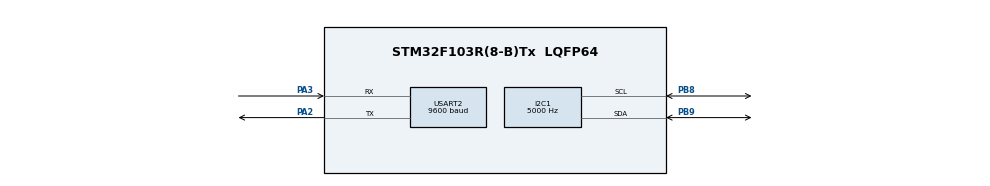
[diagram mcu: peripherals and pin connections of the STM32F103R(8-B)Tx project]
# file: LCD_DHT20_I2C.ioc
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I2C1.ClockSpeed=5000
Mcu.Family=STM32F1
Mcu.Name=STM32F103R(8-B)Tx
Mcu.Package=LQFP64
NVIC.PriorityGroup=NVIC_PRIORITYGROUP_4
NVIC.TIM2_IRQn=true\:0\:0\:false\:false\:true\:true\:true\:true
NVIC.USART2_IRQn=true\:0\:0\:false\:false\:true\:true\:true\:true
PA13.Mode=Serial_Wire
PA13.Signal=SYS_JTMS-SWDIO
PA14.Mode=Serial_Wire
PA14.Signal=SYS_JTCK-SWCLK
PA2.Mode=Asynchronous
PA2.Signal=USART2_TX
PA3.Mode=Asynchronous
PA3.Signal=USART2_RX
PB8.Mode=I2C
PB8.Signal=I2C1_SCL
PB9.Mode=I2C
PB9.Signal=I2C1_SDA
ProjectManager.HeapSize=0x200
ProjectManager.StackSize=0x400
ProjectManager.TargetToolchain=STM32CubeIDE
RCC.APB1Freq_Value=8000000
RCC.APB2Freq_Value=8000000
TIM2.Period=7999
TIM2.Prescaler=10
USART2.BaudRate=9600
USART2.VirtualMode=VM_ASYNC
USART2.WordLength=WORDLENGTH_8B
VP_TIM2_VS_ClockSourceINT.Mode=Internal
board=custom

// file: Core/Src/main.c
/* USER CODE BEGIN Header */
/**
  ******************************************************************************
  * @file           : main.c
  * @brief          : Main program body
  ******************************************************************************
  * @attention
  *
  * Copyright (c) 2023 STMicroelectronics.
  * All rights reserved.
  *
  * This software is licensed under terms that can be found in the LICENSE file
  * in the root directory of this software component.
  * If no LICENSE file comes with this software, it is provided AS-IS.
  *
  ******************************************************************************
  */
/* USER CODE END Header */
#include "main.h"

/* USER CODE BEGIN Includes */
#include "control.h"
#include "fsm_system.h"
#include "global.h"
/* USER CODE END Includes */

//I2C_HandleTypeDef hi2c1;

TIM_HandleTypeDef htim2;

//UART_HandleTypeDef huart2;

/* USER CODE BEGIN PV */
//Scheduler scheduler;
/* USER CODE END PV */

void SystemClock_Config(void);
static void MX_GPIO_Init(void);
static void MX_I2C1_Init(void);
static void MX_TIM2_Init(void);
static void MX_USART2_UART_Init(void);

int main(void)
{

  /* MCU Configuration--------------------------------------------------------*/

  /* Reset of all peripherals, Initializes the Flash interface and the Systick. */
  HAL_Init();

  /* Configure the system clock */
  SystemClock_Config();

  /* Initialize all configured peripherals */
  MX_GPIO_Init();
  MX_I2C1_Init();
  MX_TIM2_Init();
  MX_USART2_UART_Init();
  /* USER CODE BEGIN 2 */

	HAL_TIM_Base_Start_IT(&htim2);
	HAL_UART_Receive_IT(&huart2 , &data , 1) ;
	//creat scheduler with tick = 10ms
	Scheduler_Init(&scheduler, 10);
	Scan_Address_Device(&hi2c1);
  /* USER CODE END 2 */

  /* Infinite loop */
  /* USER CODE BEGIN WHILE */

	Scheduler_Add_Task(&scheduler, fsm_system, 0, 10);
	Scheduler_Add_Task(&scheduler, Get_command, 0, 10);
  while (1)
  {

	  Scheduler_Dispatch_Task(&scheduler);
    /* USER CODE END WHILE */

  }
}

void SystemClock_Config(void)
{
  RCC_OscInitTypeDef RCC_OscInitStruct = {0};
  RCC_ClkInitTypeDef RCC_ClkInitStruct = {0};

  /** Initializes the RCC Oscillators according to the specified parameters
  * in the RCC_OscInitTypeDef structure.
  */
  RCC_OscInitStruct.OscillatorType = RCC_OSCILLATORTYPE_HSI;
  RCC_OscInitStruct.HSIState = RCC_HSI_ON;
  RCC_OscInitStruct.HSICalibrationValue = RCC_HSICALIBRATION_DEFAULT;
  RCC_OscInitStruct.PLL.PLLState = RCC_PLL_NONE;
  if (HAL_RCC_OscConfig(&RCC_OscInitStruct) != HAL_OK)
  {
    Error_Handler();
  }

  /** Initializes the CPU, AHB and APB buses clocks
  */
  RCC_ClkInitStruct.ClockType = RCC_CLOCKTYPE_HCLK|RCC_CLOCKTYPE_SYSCLK
                              |RCC_CLOCKTYPE_PCLK1|RCC_CLOCKTYPE_PCLK2;
  RCC_ClkInitStruct.SYSCLKSource = RCC_SYSCLKSOURCE_HSI;
  RCC_ClkInitStruct.AHBCLKDivider = RCC_SYSCLK_DIV1;
  RCC_ClkInitStruct.APB1CLKDivider = RCC_HCLK_DIV1;
  RCC_ClkInitStruct.APB2CLKDivider = RCC_HCLK_DIV1;

  if (HAL_RCC_ClockConfig(&RCC_ClkInitStruct, FLASH_LATENCY_0) != HAL_OK)
  {
    Error_Handler();
  }
}

static void MX_I2C1_Init(void)
{

  hi2c1.Instance = I2C1;
  hi2c1.Init.ClockSpeed = 5000;
  hi2c1.Init.DutyCycle = I2C_DUTYCYCLE_2;
  hi2c1.Init.OwnAddress1 = 0;
  hi2c1.Init.AddressingMode = I2C_ADDRESSINGMODE_7BIT;
  hi2c1.Init.DualAddressMode = I2C_DUALADDRESS_DISABLE;
  hi2c1.Init.OwnAddress2 = 0;
  hi2c1.Init.GeneralCallMode = I2C_GENERALCALL_DISABLE;
  hi2c1.Init.NoStretchMode = I2C_NOSTRETCH_DISABLE;
  if (HAL_I2C_Init(&hi2c1) != HAL_OK)
  {
    Error_Handler();
  }

}

static void MX_TIM2_Init(void)
{

  TIM_ClockConfigTypeDef sClockSourceConfig = {0};
  TIM_MasterConfigTypeDef sMasterConfig = {0};

  htim2.Instance = TIM2;
  htim2.Init.Prescaler = 10;
  htim2.Init.CounterMode = TIM_COUNTERMODE_UP;
  htim2.Init.Period = 7999;
  htim2.Init.ClockDivision = TIM_CLOCKDIVISION_DIV1;
  htim2.Init.AutoReloadPreload = TIM_AUTORELOAD_PRELOAD_DISABLE;
  if (HAL_TIM_Base_Init(&htim2) != HAL_OK)
  {
    Error_Handler();
  }
  sClockSourceConfig.ClockSource = TIM_CLOCKSOURCE_INTERNAL;
  if (HAL_TIM_ConfigClockSource(&htim2, &sClockSourceConfig) != HAL_OK)
  {
    Error_Handler();
  }
  sMasterConfig.MasterOutputTrigger = TIM_TRGO_RESET;
  sMasterConfig.MasterSlaveMode = TIM_MASTERSLAVEMODE_DISABLE;
  if (HAL_TIMEx_MasterConfigSynchronization(&htim2, &sMasterConfig) != HAL_OK)
  {
    Error_Handler();
  }

}

static void MX_USART2_UART_Init(void)
{

  huart2.Instance = USART2;
  huart2.Init.BaudRate = 9600;
  huart2.Init.WordLength = UART_WORDLENGTH_8B;
  huart2.Init.StopBits = UART_STOPBITS_1;
  huart2.Init.Parity = UART_PARITY_NONE;
  huart2.Init.Mode = UART_MODE_TX_RX;
  huart2.Init.HwFlowCtl = UART_HWCONTROL_NONE;
  huart2.Init.OverSampling = UART_OVERSAMPLING_16;
  if (HAL_UART_Init(&huart2) != HAL_OK)
  {
    Error_Handler();
  }

}

static void MX_GPIO_Init(void)
{

  /* GPIO Ports Clock Enable */
  __HAL_RCC_GPIOA_CLK_ENABLE();
  __HAL_RCC_GPIOB_CLK_ENABLE();

}

/* USER CODE BEGIN 4 */
void HAL_TIM_PeriodElapsedCallback(TIM_HandleTypeDef *htim){
	Scheduler_Update(&scheduler);

}
/* USER CODE END 4 */

void Error_Handler(void)
{
  __disable_irq();
  while (1)
  {
  }
}
